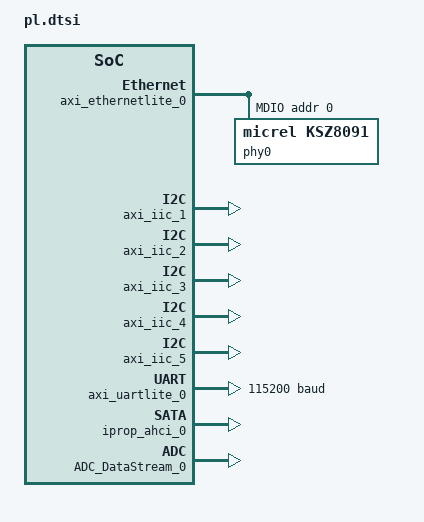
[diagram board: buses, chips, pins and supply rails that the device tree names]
/*
 * CAUTION: This file is automatically generated by Xilinx.
 * Version:  
 * Today is: Wed Apr 20 14:13:36 2016
*/


/ {
	amba_pl: amba_pl {
		#address-cells = <1>;
		#size-cells = <1>;
		compatible = "simple-bus";
		ranges ;
		axi_ethernetlite_0: ethernet@40e00000 {
			compatible = "xlnx,xps-ethernetlite-1.00.a";
			device_type = "network";
			interrupt-parent = <&intc>;
			interrupts = <0 30 1>;
			reg = <0x40e00000 0x10000>;
			xlnx,duplex = <0x1>;
			xlnx,include-global-buffers = <0x1>;
			xlnx,include-internal-loopback = <0x0>;
			xlnx,include-mdio = <0x1>;
			xlnx,rx-ping-pong = <0x1>;
			xlnx,s-axi-id-width = <0x1>;
			xlnx,tx-ping-pong = <0x1>;
			xlnx,use-internal = <0x0>;
			axi_ethernetlite_0_mdio: mdio {
				#address-cells = <1>;
				#size-cells = <0>;
				phy0:phy@0{
					compatible="micrel,ksz8091";
					device_type="ethernet-phy";
					reg=<0>;
				};
			};
		};
		axi_gpio_0: gpio@41200000 {
			#gpio-cells = <2>;
			compatible = "xlnx,xps-gpio-1.00.a";
			gpio-controller ;
			reg = <0x41200000 0x10000>;
			xlnx,all-inputs = <0x0>;
			xlnx,all-inputs-2 = <0x0>;
			xlnx,all-outputs = <0x1>;
			xlnx,all-outputs-2 = <0x0>;
			xlnx,dout-default = <0x00000000>;
			xlnx,dout-default-2 = <0x00000000>;
			xlnx,gpio-width = <0x8>;
			xlnx,gpio2-width = <0x20>;
			xlnx,interrupt-present = <0x0>;
			xlnx,is-dual = <0x0>;
			xlnx,tri-default = <0xFFFFFFFF>;
			xlnx,tri-default-2 = <0xFFFFFFFF>;
		};
		axi_gpio_1: gpio@41210000 {
			#gpio-cells = <2>;
			compatible = "xlnx,xps-gpio-1.00.a";
			gpio-controller ;
			reg = <0x41210000 0x10000>;
			xlnx,all-inputs = <0x1>;
			xlnx,all-inputs-2 = <0x0>;
			xlnx,all-outputs = <0x0>;
			xlnx,all-outputs-2 = <0x0>;
			xlnx,dout-default = <0x00000000>;
			xlnx,dout-default-2 = <0x00000000>;
			xlnx,gpio-width = <0x2>;
			xlnx,gpio2-width = <0x20>;
			xlnx,interrupt-present = <0x0>;
			xlnx,is-dual = <0x0>;
			xlnx,tri-default = <0xFFFFFFFF>;
			xlnx,tri-default-2 = <0xFFFFFFFF>;
		};
		axi_iic_1: i2c@41600000 {
			#address-cells = <1>;
			#size-cells = <0>;
			compatible = "xlnx,xps-iic-2.00.a";
			reg = <0x41600000 0x10000>;
		};
		axi_iic_2: i2c@41610000 {
			#address-cells = <1>;
			#size-cells = <0>;
			compatible = "xlnx,xps-iic-2.00.a";
			reg = <0x41610000 0x10000>;
		};
		axi_iic_3: i2c@41620000 {
			#address-cells = <1>;
			#size-cells = <0>;
			compatible = "xlnx,xps-iic-2.00.a";
			reg = <0x41620000 0x10000>;
		};
		axi_iic_4: i2c@41630000 {
			#address-cells = <1>;
			#size-cells = <0>;
			compatible = "xlnx,xps-iic-2.00.a";
			reg = <0x41630000 0x10000>;
		};
		axi_iic_5: i2c@41640000 {
			#address-cells = <1>;
			#size-cells = <0>;
			compatible = "xlnx,xps-iic-2.00.a";
			reg = <0x41640000 0x10000>;
		};
		axi_uartlite_0: serial@42c00000 {
			clock-names = "ref_clk";
			clocks = "clkc 0";
			compatible = "xlnx,xps-uartlite-1.00.a";
			current-speed = <115200>;
			device_type = "serial";
			port-number = <1>;
			reg = <0x42c00000 0x10000>;
			xlnx,baudrate = <0x2580>;
			xlnx,data-bits = <0x8>;
			xlnx,odd-parity = <0x0>;
			xlnx,s-axi-aclk-freq-hz-d = "50.0";
			xlnx,use-parity = <0x0>;
		};
		iprop_ahci_0: iprop_ahci@43c00000 {
			compatible = "xlnx,iprop-ahci-1.0","xlnx,ahci","snps,spear-ahci";
			interrupt-parent = <&intc>;
			interrupts = <0 29 4>;
			reg = <0x43c00000 0x10000>;
			xlnx,addr-pipe-depth = <0x1>;
			xlnx,dphase-timeout = <0x8>;
			xlnx,length-width = <0xc>;
			xlnx,max-burst-len = <0x100>;
			xlnx,native-data-width = <0x40>;
			xlnx,num-mem = <0x1>;
			xlnx,num-reg = <0x0>;
			xlnx,s-axi-min-size = <0x000001FF>;
			xlnx,slv-awidth = <0x20>;
			xlnx,slv-dwidth = <0x20>;
			xlnx,use-wstrb = <0x0>;
		};
		ADC_DataStream_0: ADC_DataStream@50000000 {
			compatible = "xlnx,ADC-DataStream-1.0";
			interrupt-parent = <&intc>;
			interrupts = <0 31 4>;
			reg = <0x60000000 0x10000>;
		};
		axi_fifo_mm_s_0: axi_fifo_mm_s@43c20000 {
			compatible = "generic-uio";
			interrupt-parent = <&intc>;
			interrupts = <0 32 4>;
			reg = <0x43c20000 0x10000>;
			xlnx,axi-str-rxd-protocol = "XIL_AXI_STREAM_ETH_DATA";
			xlnx,axi-str-rxd-tdata-width = <0x20>;
			xlnx,axi-str-txc-protocol = "XIL_AXI_STREAM_ETH_CTRL";
			xlnx,axi-str-txc-tdata-width = <0x20>;
			xlnx,axi-str-txd-protocol = "XIL_AXI_STREAM_ETH_DATA";
			xlnx,axi-str-txd-tdata-width = <0x20>;
			xlnx,axis-tdest-width = <0x4>;
			xlnx,axis-tid-width = <0x4>;
			xlnx,axis-tuser-width = <0x4>;
			xlnx,data-interface-type = <0x1>;
			xlnx,has-axis-tdest = <0x0>;
			xlnx,has-axis-tid = <0x0>;
			xlnx,has-axis-tkeep = <0x0>;
			xlnx,has-axis-tstrb = <0x0>;
			xlnx,has-axis-tuser = <0x0>;
			xlnx,rx-fifo-depth = <0x200>;
			xlnx,rx-fifo-pe-threshold = <0x2>;
			xlnx,rx-fifo-pf-threshold = <0x1fb>;
			xlnx,s-axi-id-width = <0x1>;
			xlnx,s-axi4-data-width = <0x20>;
			xlnx,tx-fifo-depth = <0x200>;
			xlnx,tx-fifo-pe-threshold = <0x2>;
			xlnx,tx-fifo-pf-threshold = <0x1fb>;
			xlnx,use-rx-cut-through = <0x0>;
			xlnx,use-rx-data = <0x1>;
			xlnx,use-tx-ctrl = <0x0>;
			xlnx,use-tx-cut-through = <0x0>;
			xlnx,use-tx-data = <0x0>;
		};
		axi_gpio_2: gpio@41220000 {
			#gpio-cells = <2>;
			compatible = "xlnx,xps-gpio-1.00.a";
			gpio-controller ;
			reg = <0x41220000 0x10000>;
			xlnx,all-inputs = <0x0>;
			xlnx,all-inputs-2 = <0x0>;
			xlnx,all-outputs = <0x1>;
			xlnx,all-outputs-2 = <0x0>;
			xlnx,dout-default = <0x00000000>;
			xlnx,dout-default-2 = <0x00000000>;
			xlnx,gpio-width = <0x2>;
			xlnx,gpio2-width = <0x20>;
			xlnx,interrupt-present = <0x0>;
			xlnx,is-dual = <0x0>;
			xlnx,tri-default = <0xFFFFFFFF>;
			xlnx,tri-default-2 = <0xFFFFFFFF>;
		};
		axi_traffic_gen_0: axi_traffic_gen@43c30000 {
			compatible = "xlnx,axi-traffic-gen";
			reg = <0x43c30000 0x10000>;
			xlnx,device-id = <0>;
		};
	};
};
